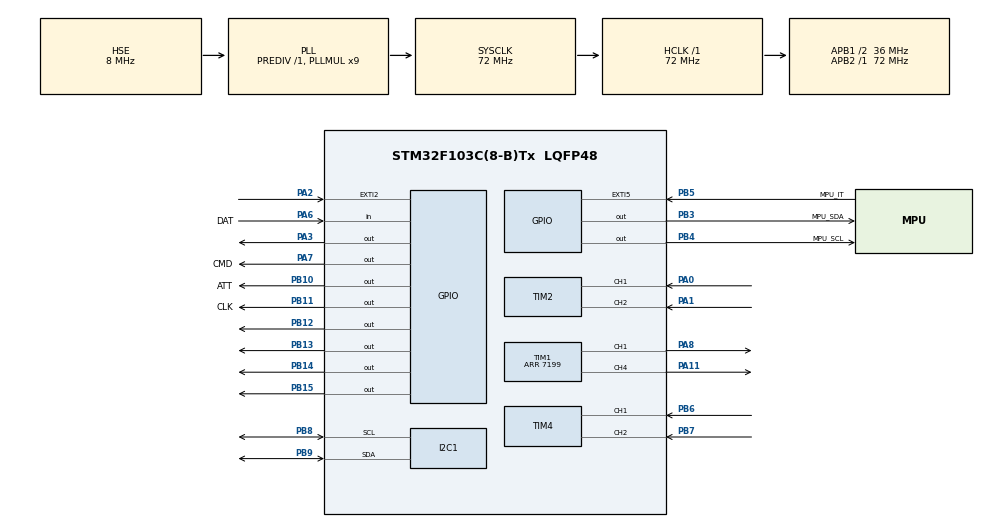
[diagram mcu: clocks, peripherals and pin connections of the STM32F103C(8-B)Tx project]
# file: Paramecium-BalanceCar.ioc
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FREERTOS.Queues01=oledDisplayQueue,8,OLED_Message_t,0,Dynamic,NULL,NULL;mpu6050DataQueue,1,MPU6050_Data_t,0,Dynamic,NULL,NULL;ps2DataQueue,1,rc_ps2_t *,0,Dynamic,NULL,NULL
FREERTOS.Tasks01=chassisControl,40,1024,chassisControlTask,As weak,NULL,Static,chassisControlBuffer,chassisControlControlBlock;mpu6050,24,128,mpu6050Task,As external,NULL,Static,mpu6050TaskBuffer,mpu6050TaskControlBlock;oledDisplay,24,128,oledDisplayTask,As external,NULL,Static,oledDisplayTaskBuffer,oledDisplayTaskControlBlock;ps2Controller,24,128,ps2ControllerTask,As external,NULL,Static,ps2ControllerTaBuffer,ps2ControllerTaControlBlock
I2C1.I2C_Mode=I2C_Fast
Mcu.Family=STM32F1
Mcu.Name=STM32F103C(8-B)Tx
Mcu.Package=LQFP48
NVIC.PriorityGroup=NVIC_PRIORITYGROUP_4
NVIC.TIM3_IRQn=true\:15\:0\:false\:false\:true\:false\:false\:true\:true
NVIC.TimeBase=TIM3_IRQn
NVIC.TimeBaseIP=TIM3
PA0-WKUP.Signal=S_TIM2_CH1_ETR
PA1.Signal=S_TIM2_CH2
PA11.Signal=S_TIM1_CH4
PA13.Mode=Serial_Wire
PA13.Signal=SYS_JTMS-SWDIO
PA14.Mode=Serial_Wire
PA14.Signal=SYS_JTCK-SWCLK
PA2.GPIO_ModeDefaultEXTI=GPIO_MODE_IT_RISING_FALLING
PA2.Signal=GPXTI2
PA3.GPIO_Speed=GPIO_SPEED_FREQ_HIGH
PA3.Signal=GPIO_Output
PA6.GPIO_Label=DAT
PA6.GPIO_PuPd=GPIO_PULLUP
PA6.Signal=GPIO_Input
PA7.GPIO_Label=CMD
PA7.GPIO_Speed=GPIO_SPEED_FREQ_HIGH
PA7.PinState=GPIO_PIN_SET
PA7.Signal=GPIO_Output
PA8.Signal=S_TIM1_CH1
PB10.GPIO_Label=ATT
PB10.GPIO_ModeDefaultOutputPP=GPIO_MODE_OUTPUT_PP
PB10.GPIO_Speed=GPIO_SPEED_FREQ_HIGH
PB10.PinState=GPIO_PIN_SET
PB10.Signal=GPIO_Output
PB11.GPIO_Label=CLK
PB11.GPIO_Speed=GPIO_SPEED_FREQ_HIGH
PB11.PinState=GPIO_PIN_SET
PB11.Signal=GPIO_Output
PB12.GPIO_Speed=GPIO_SPEED_FREQ_HIGH
PB12.Signal=GPIO_Output
PB13.GPIO_Speed=GPIO_SPEED_FREQ_HIGH
PB13.Signal=GPIO_Output
PB14.GPIO_Speed=GPIO_SPEED_FREQ_HIGH
PB14.Signal=GPIO_Output
PB15.GPIO_Speed=GPIO_SPEED_FREQ_HIGH
PB15.Signal=GPIO_Output
PB3.GPIO_Label=MPU_SDA
PB3.GPIO_ModeDefaultOutputPP=GPIO_MODE_OUTPUT_OD
PB3.GPIO_PuPd=GPIO_PULLUP
PB3.GPIO_Speed=GPIO_SPEED_FREQ_HIGH
PB3.PinState=GPIO_PIN_SET
PB3.Signal=GPIO_Output
PB4.GPIO_Label=MPU_SCL
PB4.GPIO_ModeDefaultOutputPP=GPIO_MODE_OUTPUT_OD
PB4.GPIO_PuPd=GPIO_PULLUP
PB4.GPIO_Speed=GPIO_SPEED_FREQ_HIGH
PB4.PinState=GPIO_PIN_SET
PB4.Signal=GPIO_Output
PB5.GPIO_Label=MPU_IT
PB5.GPIO_PuPd=GPIO_PULLDOWN
PB5.Signal=GPXTI5
PB6.Signal=S_TIM4_CH1
PB7.Signal=S_TIM4_CH2
PB8.Mode=I2C
PB8.Signal=I2C1_SCL
PB9.Mode=I2C
PB9.Signal=I2C1_SDA
PC14-OSC32_IN.Mode=LSE-External-Oscillator
PC14-OSC32_IN.Signal=RCC_OSC32_IN
PC15-OSC32_OUT.Mode=LSE-External-Oscillator
PC15-OSC32_OUT.Signal=RCC_OSC32_OUT
PD0-OSC_IN.Mode=HSE-External-Oscillator
PD0-OSC_IN.Signal=RCC_OSC_IN
PD1-OSC_OUT.Mode=HSE-External-Oscillator
PD1-OSC_OUT.Signal=RCC_OSC_OUT
ProjectManager.HeapSize=0x200
ProjectManager.StackSize=0x400
ProjectManager.TargetToolchain=MDK-ARM V5.32
RCC.AHBFreq_Value=72000000
RCC.APB1CLKDivider=RCC_HCLK_DIV2
RCC.APB1Freq_Value=36000000
RCC.APB1TimFreq_Value=72000000
RCC.APB2Freq_Value=72000000
RCC.APB2TimFreq_Value=72000000
RCC.HCLKFreq_Value=72000000
RCC.PLLMUL=RCC_PLL_MUL9
RCC.PLLSourceVirtual=RCC_PLLSOURCE_HSE
RCC.SYSCLKFreq_VALUE=72000000
RCC.SYSCLKSource=RCC_SYSCLKSOURCE_PLLCLK
RCC.USBFreq_Value=72000000
SH.S_TIM1_CH1.0=TIM1_CH1,PWM Generation1 CH1
SH.S_TIM1_CH4.0=TIM1_CH4,PWM Generation4 CH4
SH.S_TIM2_CH1_ETR.0=TIM2_CH1,Encoder_Interface
SH.S_TIM2_CH2.0=TIM2_CH2,Encoder_Interface
SH.S_TIM4_CH1.0=TIM4_CH1,Encoder_Interface
SH.S_TIM4_CH2.0=TIM4_CH2,Encoder_Interface
TIM1.Channel-PWM\ Generation1\ CH1=TIM_CHANNEL_1
TIM1.Channel-PWM\ Generation4\ CH4=TIM_CHANNEL_4
TIM1.Period=7199
TIM1.Pulse-PWM\ Generation1\ CH1=7200
TIM2.EncoderMode=TIM_ENCODERMODE_TI12
TIM4.EncoderMode=TIM_ENCODERMODE_TI12
VP_FREERTOS_VS_CMSIS_V2.Mode=CMSIS_V2
VP_SYS_VS_tim3.Mode=TIM3
board=custom

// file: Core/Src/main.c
/* USER CODE BEGIN Header */
/**
  ******************************************************************************
  * @file           : main.c
  * @brief          : Main program body
  ******************************************************************************
  * @attention
  *
  * Copyright (c) 2024 STMicroelectronics.
  * All rights reserved.
  *
  * This software is licensed under terms that can be found in the LICENSE file
  * in the root directory of this software component.
  * If no LICENSE file comes with this software, it is provided AS-IS.
  *
  ******************************************************************************
  */
/* USER CODE END Header */
#include "main.h"
#include "cmsis_os.h"
#include "i2c.h"
#include "tim.h"
#include "gpio.h"

void SystemClock_Config(void);
void MX_FREERTOS_Init(void);

int main(void)
{

  /* MCU Configuration--------------------------------------------------------*/

  /* Reset of all peripherals, Initializes the Flash interface and the Systick. */
  HAL_Init();

  /* Configure the system clock */
  SystemClock_Config();

  /* Initialize all configured peripherals */
  MX_GPIO_Init();
  MX_I2C1_Init();
  MX_TIM1_Init();
  MX_TIM2_Init();
  MX_TIM4_Init();

  /* Init scheduler */
  osKernelInitialize();

  /* Call init function for freertos objects (in cmsis_os2.c) */
  MX_FREERTOS_Init();

  /* Start scheduler */
  osKernelStart();

  /* We should never get here as control is now taken by the scheduler */

  /* Infinite loop */
  while (1)
  {

  }
}

void SystemClock_Config(void)
{
  RCC_OscInitTypeDef RCC_OscInitStruct = {0};
  RCC_ClkInitTypeDef RCC_ClkInitStruct = {0};

  /** Initializes the RCC Oscillators according to the specified parameters
  * in the RCC_OscInitTypeDef structure.
  */
  RCC_OscInitStruct.OscillatorType = RCC_OSCILLATORTYPE_HSE;
  RCC_OscInitStruct.HSEState = RCC_HSE_ON;
  RCC_OscInitStruct.HSEPredivValue = RCC_HSE_PREDIV_DIV1;
  RCC_OscInitStruct.HSIState = RCC_HSI_ON;
  RCC_OscInitStruct.PLL.PLLState = RCC_PLL_ON;
  RCC_OscInitStruct.PLL.PLLSource = RCC_PLLSOURCE_HSE;
  RCC_OscInitStruct.PLL.PLLMUL = RCC_PLL_MUL9;
  if (HAL_RCC_OscConfig(&RCC_OscInitStruct) != HAL_OK)
  {
    Error_Handler();
  }

  /** Initializes the CPU, AHB and APB buses clocks
  */
  RCC_ClkInitStruct.ClockType = RCC_CLOCKTYPE_HCLK|RCC_CLOCKTYPE_SYSCLK
                              |RCC_CLOCKTYPE_PCLK1|RCC_CLOCKTYPE_PCLK2;
  RCC_ClkInitStruct.SYSCLKSource = RCC_SYSCLKSOURCE_PLLCLK;
  RCC_ClkInitStruct.AHBCLKDivider = RCC_SYSCLK_DIV1;
  RCC_ClkInitStruct.APB1CLKDivider = RCC_HCLK_DIV2;
  RCC_ClkInitStruct.APB2CLKDivider = RCC_HCLK_DIV1;

  if (HAL_RCC_ClockConfig(&RCC_ClkInitStruct, FLASH_LATENCY_2) != HAL_OK)
  {
    Error_Handler();
  }
}

void HAL_TIM_PeriodElapsedCallback(TIM_HandleTypeDef *htim)
{
  if (htim->Instance == TIM3) {
    HAL_IncTick();
  }
}

void Error_Handler(void)
{
  __disable_irq();
  while (1)
  {
  }
}

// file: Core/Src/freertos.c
/* USER CODE BEGIN Header */
/**
  ******************************************************************************
  * File Name          : freertos.c
  * Description        : Code for freertos applications
  ******************************************************************************
  * @attention
  *
  * Copyright (c) 2024 STMicroelectronics.
  * All rights reserved.
  *
  * This software is licensed under terms that can be found in the LICENSE file
  * in the root directory of this software component.
  * If no LICENSE file comes with this software, it is provided AS-IS.
  *
  ******************************************************************************
  */
/* USER CODE END Header */

#include "FreeRTOS.h"
#include "task.h"
#include "main.h"
#include "cmsis_os.h"

/* USER CODE BEGIN Includes */
#include "chassis_task.h"
#include "mpu6050_task.h"
#include "oled_task.h"
#include "ps2_task.h"
/* USER CODE END Includes */

typedef StaticTask_t osStaticThreadDef_t;

/* Definitions for chassisControl */
osThreadId_t chassisControlHandle;
uint32_t chassisControlBuffer[ 1024 ];
osStaticThreadDef_t chassisControlControlBlock;
const osThreadAttr_t chassisControl_attributes = {
  .name = "chassisControl",
  .cb_mem = &chassisControlControlBlock,
  .cb_size = sizeof(chassisControlControlBlock),
  .stack_mem = &chassisControlBuffer[0],
  .stack_size = sizeof(chassisControlBuffer),
  .priority = (osPriority_t) osPriorityHigh,
};
/* Definitions for mpu6050 */
osThreadId_t mpu6050Handle;
uint32_t mpu6050TaskBuffer[ 128 ];
osStaticThreadDef_t mpu6050TaskControlBlock;
const osThreadAttr_t mpu6050_attributes = {
  .name = "mpu6050",
  .cb_mem = &mpu6050TaskControlBlock,
  .cb_size = sizeof(mpu6050TaskControlBlock),
  .stack_mem = &mpu6050TaskBuffer[0],
  .stack_size = sizeof(mpu6050TaskBuffer),
  .priority = (osPriority_t) osPriorityNormal,
};
/* Definitions for oledDisplay */
osThreadId_t oledDisplayHandle;
uint32_t oledDisplayTaskBuffer[ 128 ];
osStaticThreadDef_t oledDisplayTaskControlBlock;
const osThreadAttr_t oledDisplay_attributes = {
  .name = "oledDisplay",
  .cb_mem = &oledDisplayTaskControlBlock,
  .cb_size = sizeof(oledDisplayTaskControlBlock),
  .stack_mem = &oledDisplayTaskBuffer[0],
  .stack_size = sizeof(oledDisplayTaskBuffer),
  .priority = (osPriority_t) osPriorityNormal,
};
/* Definitions for ps2Controller */
osThreadId_t ps2ControllerHandle;
uint32_t ps2ControllerTaBuffer[ 128 ];
osStaticThreadDef_t ps2ControllerTaControlBlock;
const osThreadAttr_t ps2Controller_attributes = {
  .name = "ps2Controller",
  .cb_mem = &ps2ControllerTaControlBlock,
  .cb_size = sizeof(ps2ControllerTaControlBlock),
  .stack_mem = &ps2ControllerTaBuffer[0],
  .stack_size = sizeof(ps2ControllerTaBuffer),
  .priority = (osPriority_t) osPriorityNormal,
};
/* Definitions for oledDisplayQueue */
osMessageQueueId_t oledDisplayQueueHandle;
const osMessageQueueAttr_t oledDisplayQueue_attributes = {
  .name = "oledDisplayQueue"
};
/* Definitions for mpu6050DataQueue */
osMessageQueueId_t mpu6050DataQueueHandle;
const osMessageQueueAttr_t mpu6050DataQueue_attributes = {
  .name = "mpu6050DataQueue"
};
/* Definitions for ps2DataQueue */
osMessageQueueId_t ps2DataQueueHandle;
const osMessageQueueAttr_t ps2DataQueue_attributes = {
  .name = "ps2DataQueue"
};

void chassisControlTask(void *argument);
extern void mpu6050Task(void *argument);
extern void oledDisplayTask(void *argument);
extern void ps2ControllerTask(void *argument);

void MX_FREERTOS_Init(void); /* (MISRA C 2004 rule 8.1) */

void MX_FREERTOS_Init(void) {

  /* Create the queue(s) */
  /* creation of oledDisplayQueue */
  oledDisplayQueueHandle = osMessageQueueNew (8, sizeof(OLED_Message_t), &oledDisplayQueue_attributes);

  /* creation of mpu6050DataQueue */
  mpu6050DataQueueHandle = osMessageQueueNew (1, sizeof(MPU6050_Data_t), &mpu6050DataQueue_attributes);

  /* creation of ps2DataQueue */
  ps2DataQueueHandle = osMessageQueueNew (1, sizeof(rc_ps2_t *), &ps2DataQueue_attributes);

  /* Create the thread(s) */
  /* creation of chassisControl */
  chassisControlHandle = osThreadNew(chassisControlTask, NULL, &chassisControl_attributes);

  /* creation of mpu6050 */
  mpu6050Handle = osThreadNew(mpu6050Task, NULL, &mpu6050_attributes);

  /* creation of oledDisplay */
  oledDisplayHandle = osThreadNew(oledDisplayTask, NULL, &oledDisplay_attributes);

  /* creation of ps2Controller */
  ps2ControllerHandle = osThreadNew(ps2ControllerTask, NULL, &ps2Controller_attributes);

}

__weak void chassisControlTask(void *argument)
{
  for(;;)
  {
    osDelay(1);
  }
}
